# AT90USB1287 device description
Architecture: AVR8; Family: megaAVR
Registers are 8-bit, access not given, no defined reset value unless marked. A register's access mark holds for its fields unless they carry their own. Offsets are from the block's base; [hi:lo] are bit positions.

## TWI — Two Wire Serial Interface
Instances: TWI 0x00
0xB8 TWBR — TWI Bit Rate register
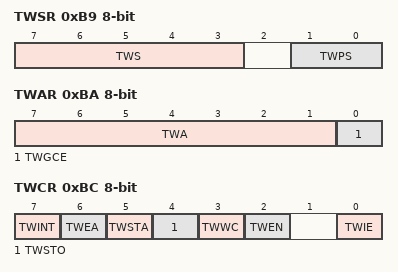
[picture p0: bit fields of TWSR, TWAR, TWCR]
0xB9 TWSR — TWI Status Register
  [7:3] TWS (bit 3 of the value upward) — TWI Status
  [1:0] TWPS — TWI Prescaler
    0=1; 1=4; 2=16; 3=64
0xBA TWAR — TWI (Slave) Address register
  [7:1] TWA — TWI (Slave) Address register Bits
  [0] TWGCE — TWI General Call Recognition Enable Bit
0xBB TWDR — TWI Data register
0xBC TWCR — TWI Control Register
  [7] TWINT — TWI Interrupt Flag
  [6] TWEA — TWI Enable Acknowledge Bit
  [5] TWSTA — TWI Start Condition Bit
  [4] TWSTO — TWI Stop Condition Bit
  [3] TWWC — TWI Write Collition Flag
  [2] TWEN — TWI Enable Bit
  [0] TWIE — TWI Interrupt Enable
0xBD TWAMR — TWI (Slave) Address Mask Register
  [7:1] TWAM

## SPI — Serial Peripheral Interface
Instances: SPI 0x00
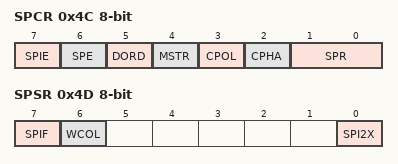
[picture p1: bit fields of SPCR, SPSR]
0x4C SPCR — SPI Control Register
  [7] SPIE — SPI Interrupt Enable
  [6] SPE — SPI Enable
  [5] DORD — Data Order
  [4] MSTR — Master/Slave Select
  [3] CPOL — Clock polarity
  [2] CPHA — Clock Phase
  [1:0] SPR — SPI Clock Rate Selects
    0=fosc/4; 1=fosc/16; 2=fosc/64; 3=fosc/128; 4=fosc/2; 5=fosc/8; 6=fosc/32; 7=fosc/64
0x4D SPSR — SPI Status Register
  [7] SPIF — SPI Interrupt Flag
  [6] WCOL — Write Collision Flag
  [0] SPI2X — Double SPI Speed Bit
0x4E SPDR — SPI Data Register

## USART1 — USART
Instances: USART1 0x00
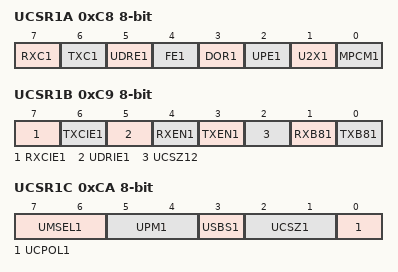
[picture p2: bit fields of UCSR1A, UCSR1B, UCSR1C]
0xC8 UCSR1A — USART Control and Status Register A
  [7] RXC1 — USART Receive Complete
  [6] TXC1 — USART Transmitt Complete
  [5] UDRE1 — USART Data Register Empty
  [4] FE1 — Framing Error
  [3] DOR1 — Data overRun
  [2] UPE1 — Parity Error
  [1] U2X1 — Double the USART transmission speed
  [0] MPCM1 — Multi-processor Communication Mode
0xC9 UCSR1B — USART Control and Status Register B
  [7] RXCIE1 — RX Complete Interrupt Enable
  [6] TXCIE1 — TX Complete Interrupt Enable
  [5] UDRIE1 — USART Data register Empty Interrupt Enable
  [4] RXEN1 — Receiver Enable
  [3] TXEN1 — Transmitter Enable
  [2] UCSZ12 — Character Size
  [1] RXB81 — Receive Data Bit 8
  [0] TXB81 — Transmit Data Bit 8
0xCA UCSR1C — USART Control and Status Register C
  [7:6] UMSEL1 — USART Mode Select
    0=Asynchronous USART; 1=Synchronous USART; 3=Master SPI
  [5:4] UPM1 — Parity Mode Bits
    0=Disabled; 2=Enabled, Even Parity; 3=Enabled, Odd Parity
  [3] USBS1 — Stop Bit Select
    0=1-bit; 1=2-bit
  [2:1] UCSZ1 — Character Size
  [0] UCPOL1 — Clock Polarity
0xCC UBRR1 16-bit bits used 11:0 — USART Baud Rate Register Bytes
0xCE UDR1 — USART I/O Data Register

## USB_DEVICE — USB Device Registers
Instances: USB_DEVICE 0x00
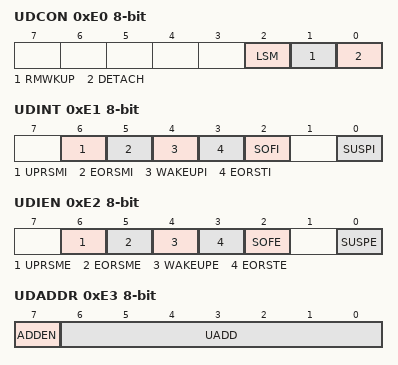
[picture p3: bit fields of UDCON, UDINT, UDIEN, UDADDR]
0xE0 UDCON
  [2] LSM, [1] RMWKUP, [0] DETACH
0xE1 UDINT
  [6] UPRSMI, [5] EORSMI, [4] WAKEUPI, [3] EORSTI, [2] SOFI, [0] SUSPI
0xE2 UDIEN
  [6] UPRSME, [5] EORSME, [4] WAKEUPE, [3] EORSTE, [2] SOFE, [0] SUSPE
0xE3 UDADDR
  [7] ADDEN, [6:0] UADD
0xE4 UDFNUM 16-bit bits used 10:0
0xE6 UDMFN
  [4] FNCERR
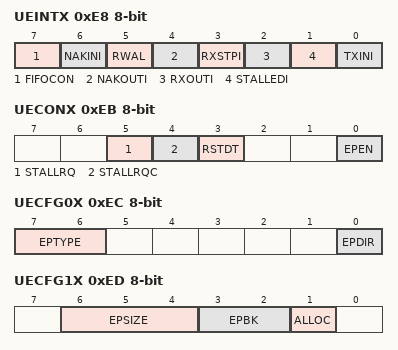
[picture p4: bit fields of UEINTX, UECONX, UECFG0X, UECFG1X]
0xE8 UEINTX
  [7] FIFOCON, [6] NAKINI, [5] RWAL, [4] NAKOUTI, [3] RXSTPI, [2] RXOUTI, [1] STALLEDI, [0] TXINI
0xE9 UENUM bits used 2:0
0xEA UERST
  [6:0] EPRST
0xEB UECONX
  [5] STALLRQ, [4] STALLRQC, [3] RSTDT, [0] EPEN
0xEC UECFG0X
  [7:6] EPTYPE, [0] EPDIR
0xED UECFG1X
  [6:4] EPSIZE, [3:2] EPBK, [1] ALLOC
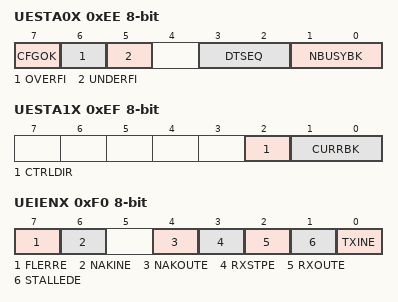
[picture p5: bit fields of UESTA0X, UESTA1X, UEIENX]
0xEE UESTA0X
  [7] CFGOK, [6] OVERFI, [5] UNDERFI, [3:2] DTSEQ, [1:0] NBUSYBK
0xEF UESTA1X
  [2] CTRLDIR, [1:0] CURRBK
0xF0 UEIENX
  [7] FLERRE, [6] NAKINE, [4] NAKOUTE, [3] RXSTPE, [2] RXOUTE, [1] STALLEDE, [0] TXINE
0xF1 UEDATX
0xF2 UEBCLX
0xF3 UEBCHX bits used 2:0
0xF4 UEINT bits used 6:0

## USB_GLOBAL — USB Controller
Instances: USB_GLOBAL 0x00
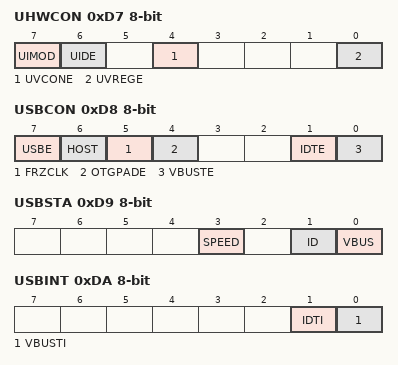
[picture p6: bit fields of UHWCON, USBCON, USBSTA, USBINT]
0xD7 UHWCON — USB Hardware Configuration Register
  [7] UIMOD, [6] UIDE, [4] UVCONE, [0] UVREGE
0xD8 USBCON — USB General Control Register
  [7] USBE, [6] HOST, [5] FRZCLK, [4] OTGPADE, [1] IDTE, [0] VBUSTE
0xD9 USBSTA
  [3] SPEED, [1] ID, [0] VBUS
0xDA USBINT
  [1] IDTI, [0] VBUSTI
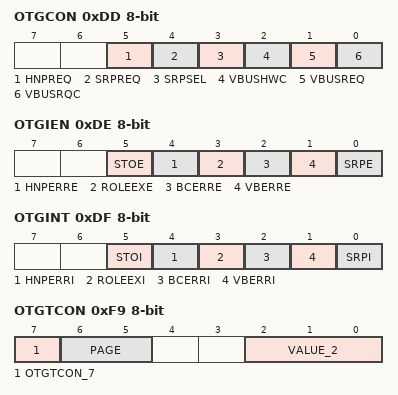
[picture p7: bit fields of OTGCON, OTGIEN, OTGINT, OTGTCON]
0xDD OTGCON
  [5] HNPREQ, [4] SRPREQ, [3] SRPSEL, [2] VBUSHWC, [1] VBUSREQ, [0] VBUSRQC
0xDE OTGIEN
  [5] STOE, [4] HNPERRE, [3] ROLEEXE, [2] BCERRE, [1] VBERRE, [0] SRPE
0xDF OTGINT
  [5] STOI, [4] HNPERRI, [3] ROLEEXI, [2] BCERRI, [1] VBERRI, [0] SRPI
0xF9 OTGTCON
  [7] OTGTCON_7, [6:5] PAGE, [2:0] VALUE_2
